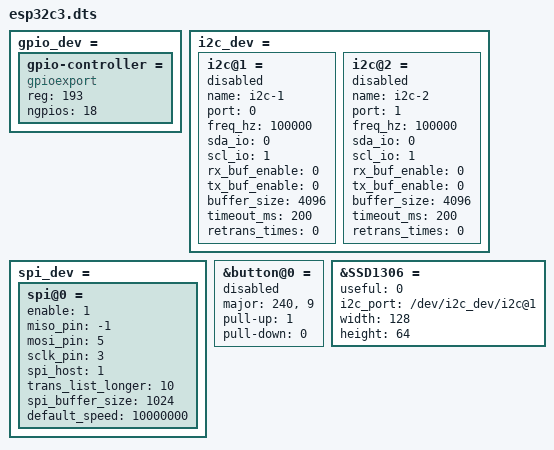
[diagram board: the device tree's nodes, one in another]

gpio_dev = {
    gpio-controller = {
        reg = <193>;               //GPIO子系统io控制器以及子设备的设备号
        ngpios = <18>;             //单片机的gpio数量
        compatible = "gpioexport";
    };
};
i2c_dev = {
     i2c@1 = {
        status  = "okey";
         name = "i2c-1";      
         port = <0>;
        freq_hz = <100000>;
        sda_io = <0>;
        scl_io = <1>;
        rx_buf_enable = <0>;
        tx_buf_enable = <0>;
        buffer_size = <4096>;
        timeout_ms = <200>;
        retrans_times = <0>;
    };
    i2c@2 = {
         status        = "Disable";
        name          = "i2c-2";
        port          = <1>;
        freq_hz       = <100000>;
        sda_io        = <0>;
        scl_io        = <1>;
        rx_buf_enable = <0>;
        tx_buf_enable = <0>;
        buffer_size   = <4096>;
        timeout_ms    = <200>;
        retrans_times = <0>;
    };
};

spi_dev = {
   spi@0 = {
        enable    = <1>;
        miso_pin  = <-1>;
        mosi_pin = <5>;
        sclk_pin = <3>;
        spi_host  = <1>;   //spi_host_2 1 spi_host_1 0
        trans_list_longer = <10>; //环形缓冲区大小
        spi_buffer_size = <1024>;
        default_speed = <10000000>;
  };
};

&button@0 = {
        status = "okey";
        major     =  <240>          //device_number
        pin       =  <9>;           // 引脚
        pull-up   =  <1>;           // 上拉
        pull-down =  <0>;           // 下拉
};

&SSD1306 = {
    useful= <0>;
    i2c_port = "/dev/i2c_dev/i2c@1";
    width = <128>;
    height = <64>;
};
